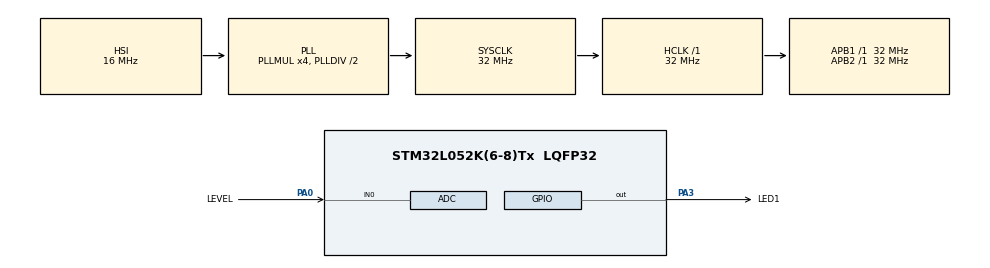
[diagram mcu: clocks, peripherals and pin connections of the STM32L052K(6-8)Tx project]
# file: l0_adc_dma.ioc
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Mcu.Family=STM32L0
RCC.MSI_VALUE=2097000
Dma.ADC.0.Mode=DMA_CIRCULAR
PA0.GPIO_Label=LEVEL
Dma.ADC.0.Priority=DMA_PRIORITY_LOW
RCC.SYSCLKSource=RCC_SYSCLKSOURCE_PLLCLK
ProjectManager.StackSize=0x400
Dma.ADC.0.PeriphDataAlignment=DMA_PDATAALIGN_HALFWORD
PA13.Signal=SYS_SWDIO
RCC.HSI16_VALUE=16000000
ProjectManager.TargetToolchain=STM32CubeIDE
Dma.ADC.0.PeriphInc=DMA_PINC_DISABLE
RCC.HCLKFreq_Value=32000000
RCC.APB2TimFreq_Value=32000000
RCC.LSE_VALUE=32768
RCC.AHBFreq_Value=32000000
Dma.ADC.0.Direction=DMA_PERIPH_TO_MEMORY
board=custom
RCC.VCOOutputFreq_Value=64000000
RCC.PLLMUL=RCC_PLLMUL_4
RCC.APB2Freq_Value=32000000
PA14.Mode=Serial_Wire
PA0.Mode=IN0
ADC.EOCSelection=ADC_EOC_SINGLE_CONV
PA13.Mode=Serial_Wire
Mcu.Name=STM32L052K(6-8)Tx
PA0.Signal=ADC_IN0
Dma.ADC.0.MemInc=DMA_MINC_ENABLE
RCC.SYSCLKFreq_VALUE=32000000
Mcu.Package=LQFP32
Dma.ADC.0.Instance=DMA1_Channel1
PA14.Signal=SYS_SWCLK
ProjectManager.HeapSize=0x200
RCC.HSI_VALUE=16000000
Dma.ADC.0.MemDataAlignment=DMA_MDATAALIGN_HALFWORD
RCC.APB1TimFreq_Value=32000000
NVIC.DMA1_Channel1_IRQn=true\:0\:0\:false\:false\:true\:false\:true
Dma.Request0=ADC
RCC.APB1Freq_Value=32000000
NVIC.ADC1_COMP_IRQn=true\:0\:0\:false\:false\:true\:true\:true
RCC.HSI48_VALUE=48000000
PA3.GPIO_Label=LED1
PA3.Signal=GPIO_Output

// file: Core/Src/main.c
/* USER CODE BEGIN Header */
/**
 ******************************************************************************
 * @file           : main.c
 * @brief          : Main program body
 ******************************************************************************
 * @attention
 *
 * <h2><center>&copy; Copyright (c) 2021 STMicroelectronics.
 * All rights reserved.</center></h2>
 *
 * This software component is licensed by ST under BSD 3-Clause license,
 * the "License"; You may not use this file except in compliance with the
 * License. You may obtain a copy of the License at:
 *                        opensource.org/licenses/BSD-3-Clause
 *
 ******************************************************************************
 */
/* USER CODE END Header */
#include "main.h"

ADC_HandleTypeDef hadc;
DMA_HandleTypeDef hdma_adc;

void SystemClock_Config(void);
static void MX_GPIO_Init(void);
static void MX_DMA_Init(void);
static void MX_ADC_Init(void);

int main(void) {
	/* USER CODE BEGIN 1 */
	uint32_t adcValue;

	/* USER CODE END 1 */

	/* MCU Configuration--------------------------------------------------------*/

	/* Reset of all peripherals, Initializes the Flash interface and the Systick. */
	HAL_Init();

	/* Configure the system clock */
	SystemClock_Config();

	/* Initialize all configured peripherals */
	MX_GPIO_Init();
	MX_DMA_Init();
	MX_ADC_Init();

	/* Infinite loop */
	/* USER CODE BEGIN WHILE */
	while (1) {
		HAL_ADC_Start(&hadc);
		HAL_ADC_PollForConversion(&hadc, 5);
		adcValue = HAL_ADC_GetValue(&hadc);
		if (adcValue > 512) {
			HAL_GPIO_WritePin(LED1_GPIO_Port, LED1_Pin, GPIO_PIN_SET);
		} else {
			HAL_GPIO_WritePin(LED1_GPIO_Port, LED1_Pin, GPIO_PIN_RESET);
		}
		HAL_ADC_Stop(&hadc);
		HAL_Delay(100);
		/* USER CODE END WHILE */

	}
}

void SystemClock_Config(void) {
	RCC_OscInitTypeDef RCC_OscInitStruct = { 0 };
	RCC_ClkInitTypeDef RCC_ClkInitStruct = { 0 };

	/** Configure the main internal regulator output voltage
	 */
	__HAL_PWR_VOLTAGESCALING_CONFIG(PWR_REGULATOR_VOLTAGE_SCALE1);
	/** Initializes the RCC Oscillators according to the specified parameters
	 * in the RCC_OscInitTypeDef structure.
	 */
	RCC_OscInitStruct.OscillatorType = RCC_OSCILLATORTYPE_HSI;
	RCC_OscInitStruct.HSIState = RCC_HSI_ON;
	RCC_OscInitStruct.HSICalibrationValue = RCC_HSICALIBRATION_DEFAULT;
	RCC_OscInitStruct.PLL.PLLState = RCC_PLL_ON;
	RCC_OscInitStruct.PLL.PLLSource = RCC_PLLSOURCE_HSI;
	RCC_OscInitStruct.PLL.PLLMUL = RCC_PLLMUL_4;
	RCC_OscInitStruct.PLL.PLLDIV = RCC_PLLDIV_2;
	if (HAL_RCC_OscConfig(&RCC_OscInitStruct) != HAL_OK) {
		Error_Handler();
	}
	/** Initializes the CPU, AHB and APB buses clocks
	 */
	RCC_ClkInitStruct.ClockType = RCC_CLOCKTYPE_HCLK | RCC_CLOCKTYPE_SYSCLK
			| RCC_CLOCKTYPE_PCLK1 | RCC_CLOCKTYPE_PCLK2;
	RCC_ClkInitStruct.SYSCLKSource = RCC_SYSCLKSOURCE_PLLCLK;
	RCC_ClkInitStruct.AHBCLKDivider = RCC_SYSCLK_DIV1;
	RCC_ClkInitStruct.APB1CLKDivider = RCC_HCLK_DIV1;
	RCC_ClkInitStruct.APB2CLKDivider = RCC_HCLK_DIV1;

	if (HAL_RCC_ClockConfig(&RCC_ClkInitStruct, FLASH_LATENCY_1) != HAL_OK) {
		Error_Handler();
	}
}

static void MX_ADC_Init(void) {

	ADC_ChannelConfTypeDef sConfig = { 0 };

	/** Configure the global features of the ADC (Clock, Resolution, Data Alignment and number of conversion)
	 */
	hadc.Instance = ADC1;
	hadc.Init.OversamplingMode = DISABLE;
	hadc.Init.ClockPrescaler = ADC_CLOCK_SYNC_PCLK_DIV2;
	hadc.Init.Resolution = ADC_RESOLUTION_12B;
	hadc.Init.SamplingTime = ADC_SAMPLETIME_1CYCLE_5;
	hadc.Init.ScanConvMode = ADC_SCAN_DIRECTION_FORWARD;
	hadc.Init.DataAlign = ADC_DATAALIGN_RIGHT;
	hadc.Init.ContinuousConvMode = DISABLE;
	hadc.Init.DiscontinuousConvMode = DISABLE;
	hadc.Init.ExternalTrigConvEdge = ADC_EXTERNALTRIGCONVEDGE_NONE;
	hadc.Init.ExternalTrigConv = ADC_SOFTWARE_START;
	hadc.Init.DMAContinuousRequests = DISABLE;
	hadc.Init.EOCSelection = ADC_EOC_SINGLE_CONV;
	hadc.Init.Overrun = ADC_OVR_DATA_PRESERVED;
	hadc.Init.LowPowerAutoWait = DISABLE;
	hadc.Init.LowPowerFrequencyMode = DISABLE;
	hadc.Init.LowPowerAutoPowerOff = DISABLE;
	if (HAL_ADC_Init(&hadc) != HAL_OK) {
		Error_Handler();
	}
	/** Configure for the selected ADC regular channel to be converted.
	 */
	sConfig.Channel = ADC_CHANNEL_0;
	sConfig.Rank = ADC_RANK_CHANNEL_NUMBER;
	if (HAL_ADC_ConfigChannel(&hadc, &sConfig) != HAL_OK) {
		Error_Handler();
	}

}

static void MX_DMA_Init(void) {

	/* DMA controller clock enable */
	__HAL_RCC_DMA1_CLK_ENABLE();

	/* DMA interrupt init */
	/* DMA1_Channel1_IRQn interrupt configuration */
	HAL_NVIC_SetPriority(DMA1_Channel1_IRQn, 0, 0);
	HAL_NVIC_EnableIRQ(DMA1_Channel1_IRQn);

}

static void MX_GPIO_Init(void) {
	GPIO_InitTypeDef GPIO_InitStruct = { 0 };

	/* GPIO Ports Clock Enable */
	__HAL_RCC_GPIOA_CLK_ENABLE();

	/*Configure GPIO pin Output Level */
	HAL_GPIO_WritePin(LED1_GPIO_Port, LED1_Pin, GPIO_PIN_RESET);

	/*Configure GPIO pin : LED1_Pin */
	GPIO_InitStruct.Pin = LED1_Pin;
	GPIO_InitStruct.Mode = GPIO_MODE_OUTPUT_PP;
	GPIO_InitStruct.Pull = GPIO_NOPULL;
	GPIO_InitStruct.Speed = GPIO_SPEED_FREQ_LOW;
	HAL_GPIO_Init(LED1_GPIO_Port, &GPIO_InitStruct);

}

void Error_Handler(void) {
	__disable_irq();
	while (1) {
	}
}

/************************ (C) COPYRIGHT STMicroelectronics *****END OF FILE****/
